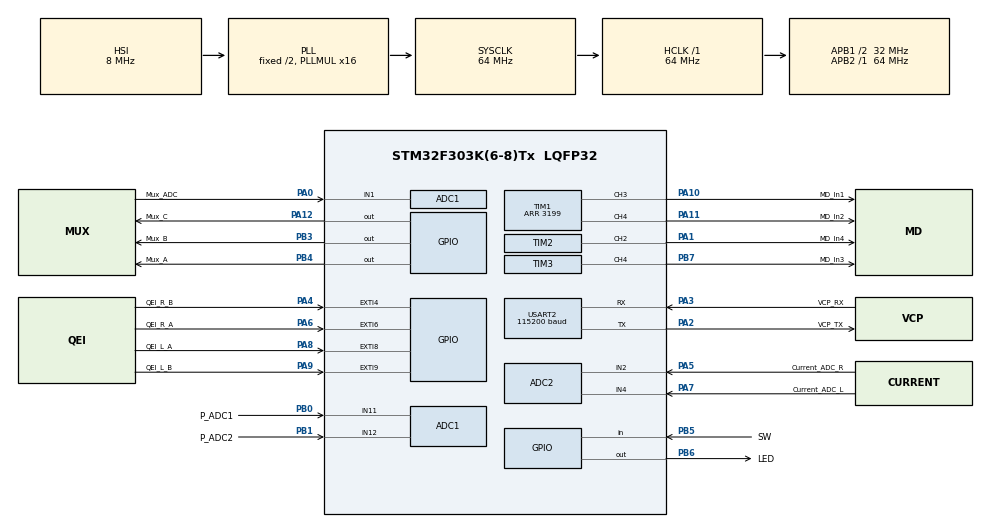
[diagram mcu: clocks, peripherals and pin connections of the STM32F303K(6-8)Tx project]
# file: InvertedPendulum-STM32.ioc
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ADC1.Channel-10\#ChannelRegularConversion=ADC_CHANNEL_11
ADC1.Channel-11\#ChannelRegularConversion=ADC_CHANNEL_12
ADC1.Channel-9\#ChannelRegularConversion=ADC_CHANNEL_1
ADC1.ContinuousConvMode=ENABLE
ADC1.DMAContinuousRequests=DISABLE
ADC1.EOCSelection=ADC_EOC_SEQ_CONV
ADC1.EnableInjectedConversion=ENABLE
ADC1.EnableRegularConversion=ENABLE
ADC1.NbrOfConversion=3
ADC1.NbrOfConversionFlag=1
ADC1.Offset-10\#ChannelRegularConversion=0
ADC1.Offset-11\#ChannelRegularConversion=0
ADC1.Offset-9\#ChannelRegularConversion=0
ADC1.OffsetNumber-10\#ChannelRegularConversion=ADC_OFFSET_NONE
ADC1.OffsetNumber-11\#ChannelRegularConversion=ADC_OFFSET_NONE
ADC1.OffsetNumber-9\#ChannelRegularConversion=ADC_OFFSET_NONE
ADC1.Rank-10\#ChannelRegularConversion=2
ADC1.Rank-11\#ChannelRegularConversion=3
ADC1.Rank-9\#ChannelRegularConversion=1
ADC1.Rank1_Channel=ADC_CHANNEL_1
ADC1.Rank2_Channel=ADC_CHANNEL_11
ADC1.Rank3_Channel=ADC_CHANNEL_12
ADC1.SamplingTime-10\#ChannelRegularConversion=ADC_SAMPLETIME_601CYCLES_5
ADC1.SamplingTime-11\#ChannelRegularConversion=ADC_SAMPLETIME_601CYCLES_5
ADC1.SamplingTime-9\#ChannelRegularConversion=ADC_SAMPLETIME_601CYCLES_5
ADC1.SamplingTimeOPAMP-10\#ChannelRegularConversion=ADC_SAMPLETIME_61CYCLES_5
ADC1.SamplingTimeOPAMP-11\#ChannelRegularConversion=ADC_SAMPLETIME_61CYCLES_5
ADC1.SamplingTimeOPAMP-9\#ChannelRegularConversion=ADC_SAMPLETIME_61CYCLES_5
ADC1.SubFamily=STM32F303x8
ADC1.master=1
ADC2.Channel-0\#ChannelRegularConversion=ADC_CHANNEL_2
ADC2.Channel-1\#ChannelRegularConversion=ADC_CHANNEL_4
ADC2.ContinuousConvMode=DISABLE
ADC2.DMAContinuousRequests=DISABLE
ADC2.EOCSelection=ADC_EOC_SEQ_CONV
ADC2.EnableInjectedConversion=ENABLE
ADC2.NbrOfConversion=2
ADC2.NbrOfConversionFlag=1
ADC2.Offset-0\#ChannelRegularConversion=0
ADC2.Offset-1\#ChannelRegularConversion=0
ADC2.OffsetNumber-0\#ChannelRegularConversion=ADC_OFFSET_NONE
ADC2.OffsetNumber-1\#ChannelRegularConversion=ADC_OFFSET_NONE
ADC2.Rank-0\#ChannelRegularConversion=1
ADC2.Rank-1\#ChannelRegularConversion=2
ADC2.SamplingTime-0\#ChannelRegularConversion=ADC_SAMPLETIME_601CYCLES_5
ADC2.SamplingTime-1\#ChannelRegularConversion=ADC_SAMPLETIME_601CYCLES_5
ADC2.SamplingTimeOPAMP-1\#ChannelRegularConversion=ADC_SAMPLETIME_61CYCLES_5
ADC2.SubFamily=STM32F303x8
Dma.ADC1.0.Direction=DMA_PERIPH_TO_MEMORY
Dma.ADC1.0.Instance=DMA1_Channel1
Dma.ADC1.0.MemDataAlignment=DMA_MDATAALIGN_HALFWORD
Dma.ADC1.0.MemInc=DMA_MINC_ENABLE
Dma.ADC1.0.Mode=DMA_CIRCULAR
Dma.ADC1.0.PeriphDataAlignment=DMA_PDATAALIGN_HALFWORD
Dma.ADC1.0.PeriphInc=DMA_PINC_DISABLE
Dma.ADC1.0.Priority=DMA_PRIORITY_LOW
Dma.ADC2.1.Direction=DMA_PERIPH_TO_MEMORY
Dma.ADC2.1.Instance=DMA1_Channel2
Dma.ADC2.1.MemDataAlignment=DMA_MDATAALIGN_HALFWORD
Dma.ADC2.1.MemInc=DMA_MINC_ENABLE
Dma.ADC2.1.Mode=DMA_CIRCULAR
Dma.ADC2.1.PeriphDataAlignment=DMA_PDATAALIGN_HALFWORD
Dma.ADC2.1.PeriphInc=DMA_PINC_DISABLE
Dma.ADC2.1.Priority=DMA_PRIORITY_LOW
Dma.Request0=ADC1
Dma.Request1=ADC2
Dma.Request2=USART2_RX
Dma.Request3=USART2_TX
Dma.USART2_RX.2.Direction=DMA_PERIPH_TO_MEMORY
Dma.USART2_RX.2.Instance=DMA1_Channel6
Dma.USART2_RX.2.MemDataAlignment=DMA_MDATAALIGN_BYTE
Dma.USART2_RX.2.MemInc=DMA_MINC_ENABLE
Dma.USART2_RX.2.Mode=DMA_NORMAL
Dma.USART2_RX.2.PeriphDataAlignment=DMA_PDATAALIGN_BYTE
Dma.USART2_RX.2.PeriphInc=DMA_PINC_DISABLE
Dma.USART2_RX.2.Priority=DMA_PRIORITY_LOW
Dma.USART2_TX.3.Direction=DMA_MEMORY_TO_PERIPH
Dma.USART2_TX.3.Instance=DMA1_Channel7
Dma.USART2_TX.3.MemDataAlignment=DMA_MDATAALIGN_BYTE
Dma.USART2_TX.3.MemInc=DMA_MINC_ENABLE
Dma.USART2_TX.3.Mode=DMA_NORMAL
Dma.USART2_TX.3.PeriphDataAlignment=DMA_PDATAALIGN_BYTE
Dma.USART2_TX.3.PeriphInc=DMA_PINC_DISABLE
Dma.USART2_TX.3.Priority=DMA_PRIORITY_LOW
Mcu.Family=STM32F3
Mcu.Name=STM32F303K(6-8)Tx
Mcu.Package=LQFP32
NVIC.ADC1_2_IRQn=true\:0\:0\:false\:false\:true\:true\:true\:true
NVIC.DMA1_Channel1_IRQn=true\:1\:0\:true\:false\:true\:false\:true\:true
NVIC.DMA1_Channel2_IRQn=true\:1\:0\:true\:false\:true\:false\:true\:true
NVIC.DMA1_Channel6_IRQn=true\:0\:0\:false\:false\:true\:false\:true\:true
NVIC.DMA1_Channel7_IRQn=true\:0\:0\:false\:false\:true\:false\:true\:true
NVIC.EXTI4_IRQn=true\:0\:0\:false\:false\:true\:true\:true\:true
NVIC.EXTI9_5_IRQn=true\:0\:0\:false\:false\:true\:true\:true\:true
NVIC.PriorityGroup=NVIC_PRIORITYGROUP_4
NVIC.TIM6_DAC1_IRQn=true\:1\:0\:true\:false\:true\:true\:true\:true
NVIC.USART2_IRQn=true\:0\:0\:false\:false\:true\:true\:true\:true
PA0.GPIO_Label=Mux_ADC
PA0.Mode=IN1-Single-Ended
PA0.Signal=ADC1_IN1
PA1.GPIO_Label=MD_In4
PA1.Signal=S_TIM2_CH2
PA10.GPIO_Label=MD_In1
PA10.Signal=S_TIM1_CH3
PA11.GPIO_Label=MD_In2
PA11.Signal=S_TIM1_CH4
PA12.GPIO_Label=Mux_C
PA12.Signal=GPIO_Output
PA13.GPIO_Label=SWDIO
PA13.Mode=Serial_Wire
PA13.Signal=SYS_JTMS-SWDIO
PA14.GPIO_Label=SWCLK
PA14.Mode=Serial_Wire
PA14.Signal=SYS_JTCK-SWCLK
PA2.GPIO_Label=VCP_TX
PA2.Mode=Asynchronous
PA2.Signal=USART2_TX
PA3.GPIO_Label=VCP_RX
PA3.Mode=Asynchronous
PA3.Signal=USART2_RX
PA4.GPIO_Label=QEI_R_B
PA4.GPIO_ModeDefaultEXTI=GPIO_MODE_IT_RISING_FALLING
PA4.GPIO_PuPd=GPIO_NOPULL
PA4.Signal=GPXTI4
PA5.GPIO_Label=Current_ADC_R
PA5.Mode=IN2-Single-Ended
PA5.Signal=ADC2_IN2
PA6.GPIO_Label=QEI_R_A
PA6.GPIO_ModeDefaultEXTI=GPIO_MODE_IT_RISING_FALLING
PA6.GPIO_PuPd=GPIO_NOPULL
PA6.Signal=GPXTI6
PA7.GPIO_Label=Current_ADC_L
PA7.Mode=IN4-Single-Ended
PA7.Signal=ADC2_IN4
PA8.GPIO_Label=QEI_L_A
PA8.GPIO_ModeDefaultEXTI=GPIO_MODE_IT_RISING_FALLING
PA8.GPIO_PuPd=GPIO_PULLUP
PA8.Signal=GPXTI8
PA9.GPIO_Label=QEI_L_B
PA9.GPIO_ModeDefaultEXTI=GPIO_MODE_IT_RISING_FALLING
PA9.GPIO_PuPd=GPIO_PULLUP
PA9.Signal=GPXTI9
PB0.GPIO_Label=P_ADC1
PB0.Mode=IN11-Single-Ended
PB0.Signal=ADC1_IN11
PB1.GPIO_Label=P_ADC2
PB1.Mode=IN12-Single-Ended
PB1.Signal=ADC1_IN12
PB3.GPIO_Label=Mux_B
PB3.Signal=GPIO_Output
PB4.GPIO_Label=Mux_A
PB4.Signal=GPIO_Output
PB5.GPIO_Label=SW
PB5.GPIO_PuPd=GPIO_PULLUP
PB5.Signal=GPIO_Input
PB6.GPIO_Label=LED
PB6.Signal=GPIO_Output
PB7.GPIO_Label=MD_In3
PB7.Signal=S_TIM3_CH4
PF0\ /\ OSC_IN.GPIO_Label=MCO
PF0\ /\ OSC_IN.Signal=RCC_OSC_IN
ProjectManager.HeapSize=0x200
ProjectManager.StackSize=0x400
ProjectManager.TargetToolchain=CMake
RCC.AHBFreq_Value=64000000
RCC.APB1CLKDivider=RCC_HCLK_DIV2
RCC.APB1Freq_Value=32000000
RCC.APB1TimFreq_Value=64000000
RCC.APB2Freq_Value=64000000
RCC.APB2TimFreq_Value=64000000
RCC.CortexFreq_Value=64000000
RCC.HCLKFreq_Value=64000000
RCC.HSE_VALUE=8000000
RCC.HSI_VALUE=8000000
RCC.PLLMUL=RCC_PLL_MUL16
RCC.SYSCLKFreq_VALUE=64000000
RCC.SYSCLKSourceVirtual=RCC_SYSCLKSOURCE_PLLCLK
SH.S_TIM1_CH3.0=TIM1_CH3,PWM Generation3 CH3
SH.S_TIM1_CH4.0=TIM1_CH4,PWM Generation4 CH4
SH.S_TIM2_CH2.0=TIM2_CH2,PWM Generation2 CH2
SH.S_TIM3_CH4.0=TIM3_CH4,PWM Generation4 CH4
TIM1.Channel-PWM\ Generation3\ CH3=TIM_CHANNEL_3
TIM1.Channel-PWM\ Generation4\ CH4=TIM_CHANNEL_4
TIM1.Period=3199
TIM2.Channel-PWM\ Generation2\ CH2=TIM_CHANNEL_2
TIM2.Period=3199
TIM3.Channel-PWM\ Generation4\ CH4=TIM_CHANNEL_4
TIM3.Period=3199
TIM6.Period=3199
TIM6.Prescaler=0
USART2.BaudRate=115200
USART2.VirtualMode-Asynchronous=VM_ASYNC
VP_TIM1_VS_ClockSourceINT.Mode=Internal
VP_TIM2_VS_ClockSourceINT.Mode=Internal
VP_TIM3_VS_ClockSourceINT.Mode=Internal
VP_TIM6_VS_ClockSourceINT.Mode=Enable_Timer
board=NUCLEO-F303K8

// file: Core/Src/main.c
/* USER CODE BEGIN Header */
/**
 ******************************************************************************
 * @file           : main.c
 * @brief          : Main program body
 ******************************************************************************
 * @attention
 *
 * Copyright (c) 2025 STMicroelectronics.
 * All rights reserved.
 *
 * This software is licensed under terms that can be found in the LICENSE file
 * in the root directory of this software component.
 * If no LICENSE file comes with this software, it is provided AS-IS.
 *
 ******************************************************************************
 */
/* USER CODE END Header */
#include "main.h"
#include "adc.h"
#include "dma.h"
#include "tim.h"
#include "usart.h"
#include "gpio.h"

/* USER CODE BEGIN Includes */
#include "stdio.h"
#include "app_wrapper.hpp"
/* USER CODE END Includes */

void SystemClock_Config(void);

/* USER CODE BEGIN 0 */
int _write(int file, char *ptr, int len)
{
  HAL_UART_Transmit(&huart2,(uint8_t *)ptr,len,10);
  return len;
}
/* USER CODE END 0 */

int main(void)
{

  /* USER CODE BEGIN 1 */
  setbuf(stdout, NULL);
  /* USER CODE END 1 */

  /* MCU Configuration--------------------------------------------------------*/

  /* Reset of all peripherals, Initializes the Flash interface and the Systick. */
  HAL_Init();

  /* Configure the system clock */
  SystemClock_Config();

  /* Initialize all configured peripherals */
  MX_GPIO_Init();
  MX_DMA_Init();
  MX_USART2_UART_Init();
  MX_ADC1_Init();
  MX_ADC2_Init();
  MX_TIM1_Init();
  MX_TIM2_Init();
  MX_TIM3_Init();
  MX_TIM6_Init();
  /* USER CODE BEGIN 2 */
  AppRun();
  /* USER CODE END 2 */

  /* Infinite loop */
  while (1) {

  }
}

void SystemClock_Config(void)
{
  RCC_OscInitTypeDef RCC_OscInitStruct = {0};
  RCC_ClkInitTypeDef RCC_ClkInitStruct = {0};
  RCC_PeriphCLKInitTypeDef PeriphClkInit = {0};

  /** Initializes the RCC Oscillators according to the specified parameters
  * in the RCC_OscInitTypeDef structure.
  */
  RCC_OscInitStruct.OscillatorType = RCC_OSCILLATORTYPE_HSI;
  RCC_OscInitStruct.HSIState = RCC_HSI_ON;
  RCC_OscInitStruct.HSICalibrationValue = RCC_HSICALIBRATION_DEFAULT;
  RCC_OscInitStruct.PLL.PLLState = RCC_PLL_ON;
  RCC_OscInitStruct.PLL.PLLSource = RCC_PLLSOURCE_HSI;
  RCC_OscInitStruct.PLL.PLLMUL = RCC_PLL_MUL16;
  if (HAL_RCC_OscConfig(&RCC_OscInitStruct) != HAL_OK)
  {
    Error_Handler();
  }

  /** Initializes the CPU, AHB and APB buses clocks
  */
  RCC_ClkInitStruct.ClockType = RCC_CLOCKTYPE_HCLK|RCC_CLOCKTYPE_SYSCLK
                              |RCC_CLOCKTYPE_PCLK1|RCC_CLOCKTYPE_PCLK2;
  RCC_ClkInitStruct.SYSCLKSource = RCC_SYSCLKSOURCE_PLLCLK;
  RCC_ClkInitStruct.AHBCLKDivider = RCC_SYSCLK_DIV1;
  RCC_ClkInitStruct.APB1CLKDivider = RCC_HCLK_DIV2;
  RCC_ClkInitStruct.APB2CLKDivider = RCC_HCLK_DIV1;

  if (HAL_RCC_ClockConfig(&RCC_ClkInitStruct, FLASH_LATENCY_2) != HAL_OK)
  {
    Error_Handler();
  }
  PeriphClkInit.PeriphClockSelection = RCC_PERIPHCLK_TIM1|RCC_PERIPHCLK_ADC12;
  PeriphClkInit.Adc12ClockSelection = RCC_ADC12PLLCLK_DIV1;
  PeriphClkInit.Tim1ClockSelection = RCC_TIM1CLK_HCLK;
  if (HAL_RCCEx_PeriphCLKConfig(&PeriphClkInit) != HAL_OK)
  {
    Error_Handler();
  }
}

void Error_Handler(void)
{
  __disable_irq();
  while (1) {
  }
}

#ifdef  USE_FULL_ASSERT
/**
  * @brief  Reports the name of the source file and the source line number
  *         where the assert_param error has occurred.
  * @param  file: pointer to the source file name
  * @param  line: assert_param error line source number
  * @retval None
  */
void assert_failed(uint8_t *file, uint32_t line)
{
  /* USER CODE BEGIN 6 */
  /* User can add his own implementation to report the file name and line
     number, ex: printf("Wrong parameters value: file %s on line %d\r\n", file,
     line) */
  /* USER CODE END 6 */
}
#endif /* USE_FULL_ASSERT */
